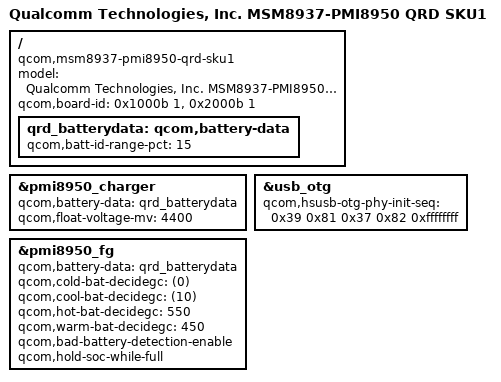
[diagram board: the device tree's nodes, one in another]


/dts-v1/;

#include "msm8937.dtsi"
#include "msm8937-pmi8950-qrd-wt87511.dtsi"

/ {
	model = "Qualcomm Technologies, Inc. MSM8937-PMI8950 QRD SKU1";
	compatible = "qcom,msm8937-pmi8950-qrd-sku1",
		   "qcom,msm8937-qrd", "qcom,msm8937", "qcom,qrd";
	qcom,board-id= <0x1000b 1>, <0x2000b 1>;
};

/ {
	qrd_batterydata: qcom,battery-data {
		qcom,batt-id-range-pct = <15>;
		#include "batterydata-qrd-sku1-4v4-2800mah.dtsi"
		#include "diego-qrd-sunwoda-4v4-2920mah.dtsi"
	};
};

&pmi8950_charger {
	qcom,battery-data = <&qrd_batterydata>;
	qcom,float-voltage-mv = <4400>;
	//qcom,chg-led-sw-controls;
	//qcom,chg-led-support;
	status = "okay";
};

&usb_otg {
	qcom,hsusb-otg-phy-init-seq =
		<0x39 0x81 0x37 0x82 0xffffffff>;
};

&pmi8950_fg {
	qcom,battery-data = <&qrd_batterydata>;
	qcom,cold-bat-decidegc = <(0)>;
	qcom,cool-bat-decidegc = <(10)>;
	qcom,hot-bat-decidegc = <550>;
	qcom,warm-bat-decidegc = <450>;
	qcom,bad-battery-detection-enable;
	qcom,hold-soc-while-full;
};

